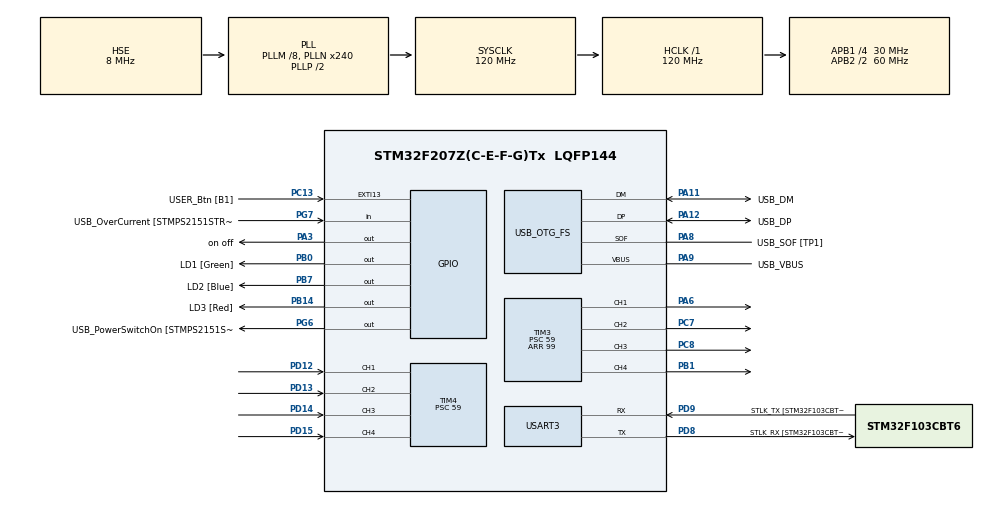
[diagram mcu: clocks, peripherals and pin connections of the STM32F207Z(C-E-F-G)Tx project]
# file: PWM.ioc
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Mcu.Family=STM32F2
Mcu.Name=STM32F207Z(C-E-F-G)Tx
Mcu.Package=LQFP144
NVIC.PriorityGroup=NVIC_PRIORITYGROUP_4
NVIC.TIM3_IRQn=true\:0\:0\:false\:false\:true\:true\:true\:true
NVIC.TIM4_IRQn=true\:0\:0\:false\:false\:true\:true\:true\:true
PA1.GPIO_Label=RMII_REF_CLK [LAN8742A-CZ-TR_REFCLK0]
PA1.Signal=ETH_REF_CLK
PA10.GPIO_Label=USB_ID
PA10.Signal=USB_OTG_FS_ID
PA11.GPIO_Label=USB_DM
PA11.Mode=Device_Only
PA11.Signal=USB_OTG_FS_DM
PA12.GPIO_Label=USB_DP
PA12.Mode=Device_Only
PA12.Signal=USB_OTG_FS_DP
PA13.GPIO_Label=TMS
PA13.Mode=Serial_Wire
PA13.Signal=SYS_JTMS-SWDIO
PA14.GPIO_Label=TCK
PA14.Mode=Serial_Wire
PA14.Signal=SYS_JTCK-SWCLK
PA2.GPIO_Label=RMII_MDIO [LAN8742A-CZ-TR_MDIO]
PA2.Signal=ETH_MDIO
PA3.GPIO_Label=on off
PA3.Signal=GPIO_Output
PA6.Signal=S_TIM3_CH1
PA7.GPIO_Label=RMII_CRS_DV [LAN8742A-CZ-TR_CRS_DV]
PA7.Signal=ETH_CRS_DV
PA8.GPIO_Label=USB_SOF [TP1]
PA8.Mode=Activate_SOF_FS
PA8.Signal=USB_OTG_FS_SOF
PA9.GPIO_Label=USB_VBUS
PA9.Mode=Activate_VBUS
PA9.Signal=USB_OTG_FS_VBUS
PB0.GPIO_Label=LD1 [Green]
PB0.Signal=GPIO_Output
PB1.Signal=S_TIM3_CH4
PB13.GPIO_Label=RMII_TXD1 [LAN8742A-CZ-TR_TXD1]
PB13.Signal=ETH_TXD1
PB14.GPIO_Label=LD3 [Red]
PB14.Signal=GPIO_Output
PB3.GPIO_Label=SWO
PB3.Signal=SYS_JTDO-SWO
PB7.GPIO_Label=LD2 [Blue]
PB7.Signal=GPIO_Output
PC1.GPIO_Label=RMII_MDC [LAN8742A-CZ-TR_MDC]
PC1.Signal=ETH_MDC
PC13.GPIO_Label=USER_Btn [B1]
PC13.Signal=GPXTI13
PC14-OSC32_IN.Mode=LSE-External-Oscillator
PC14-OSC32_IN.Signal=RCC_OSC32_IN
PC15-OSC32_OUT.Mode=LSE-External-Oscillator
PC15-OSC32_OUT.Signal=RCC_OSC32_OUT
PC4.GPIO_Label=RMII_RXD0 [LAN8742A-CZ-TR_RXD0]
PC4.Signal=ETH_RXD0
PC5.GPIO_Label=RMII_RXD1 [LAN8742A-CZ-TR_RXD1]
PC5.Signal=ETH_RXD1
PC7.Signal=S_TIM3_CH2
PC8.Signal=S_TIM3_CH3
PD12.Signal=S_TIM4_CH1
PD13.Signal=S_TIM4_CH2
PD14.Signal=S_TIM4_CH3
PD15.Signal=S_TIM4_CH4
PD8.GPIO_Label=STLK_RX [STM32F103CBT6_PA2]
PD8.Mode=Asynchronous
PD8.Signal=USART3_TX
PD9.GPIO_Label=STLK_TX [STM32F103CBT6_PA3]
PD9.Mode=Asynchronous
PD9.Signal=USART3_RX
PG11.GPIO_Label=RMII_TX_EN [LAN8742A-CZ-TR_TXEN]
PG11.Signal=ETH_TX_EN
PG13.GPIO_Label=RMII_TXD0 [LAN8742A-CZ-TR_TXD0]
PG13.Signal=ETH_TXD0
PG6.GPIO_Label=USB_PowerSwitchOn [STMPS2151STR_EN]
PG6.Signal=GPIO_Output
PG7.GPIO_Label=USB_OverCurrent [STMPS2151STR_FAULT]
PG7.Signal=GPIO_Input
PH0-OSC_IN.GPIO_Label=MCO [STM32F103CBT6_PA8]
PH0-OSC_IN.Mode=HSE-External-Oscillator
PH0-OSC_IN.Signal=RCC_OSC_IN
PH1-OSC_OUT.Mode=HSE-External-Oscillator
PH1-OSC_OUT.Signal=RCC_OSC_OUT
ProjectManager.HeapSize=0x200
ProjectManager.StackSize=0x400
ProjectManager.TargetToolchain=STM32CubeIDE
RCC.48MHZClocksFreq_Value=48000000
RCC.AHBFreq_Value=120000000
RCC.APB1CLKDivider=RCC_HCLK_DIV4
RCC.APB1Freq_Value=30000000
RCC.APB1TimFreq_Value=60000000
RCC.APB2CLKDivider=RCC_HCLK_DIV2
RCC.APB2Freq_Value=60000000
RCC.APB2TimFreq_Value=120000000
RCC.CortexFreq_Value=120000000
RCC.HCLKFreq_Value=120000000
RCC.HSE_VALUE=8000000
RCC.HSI_VALUE=16000000
RCC.PLLM=8
RCC.PLLMUL=RCC_PLL_MUL9
RCC.PLLN=240
RCC.PLLQ=5
RCC.PLLSourceVirtual=RCC_PLLSOURCE_HSE
RCC.PRESCALERUSB=RCC_USBCLKSOURCE_PLL_DIV1_5
RCC.SYSCLKFreq_VALUE=120000000
RCC.SYSCLKSource=RCC_SYSCLKSOURCE_PLLCLK
RCC.SYSCLKSourceVirtual=RCC_SYSCLKSOURCE_PLLCLK
RCC.USBFreq_Value=48000000
RCC.VCOOutputFreq_Value=240000000
SH.S_TIM3_CH1.0=TIM3_CH1,PWM Generation1 CH1
SH.S_TIM3_CH2.0=TIM3_CH2,PWM Generation2 CH2
SH.S_TIM3_CH3.0=TIM3_CH3,PWM Generation3 CH3
SH.S_TIM3_CH4.0=TIM3_CH4,PWM Generation4 CH4
SH.S_TIM4_CH1.0=TIM4_CH1,Input_Capture1_from_TI1
SH.S_TIM4_CH2.0=TIM4_CH2,Input_Capture2_from_TI2
SH.S_TIM4_CH3.0=TIM4_CH3,Input_Capture3_from_TI3
SH.S_TIM4_CH4.0=TIM4_CH4,Input_Capture4_from_TI4
TIM3.AutoReloadPreload=TIM_AUTORELOAD_PRELOAD_ENABLE
TIM3.Channel-PWM\ Generation1\ CH1=TIM_CHANNEL_1
TIM3.Channel-PWM\ Generation2\ CH2=TIM_CHANNEL_2
TIM3.Channel-PWM\ Generation3\ CH3=TIM_CHANNEL_3
TIM3.Channel-PWM\ Generation4\ CH4=TIM_CHANNEL_4
TIM3.Period=99
TIM3.Prescaler=59
TIM3.Pulse-PWM\ Generation1\ CH1=50
TIM3.Pulse-PWM\ Generation2\ CH2=50
TIM3.Pulse-PWM\ Generation3\ CH3=50
TIM3.Pulse-PWM\ Generation4\ CH4=50
TIM4.AutoReloadPreload=TIM_AUTORELOAD_PRELOAD_ENABLE
TIM4.Channel-Input_Capture1_from_TI1=TIM_CHANNEL_1
TIM4.Channel-Input_Capture2_from_TI2=TIM_CHANNEL_2
TIM4.Channel-Input_Capture3_from_TI3=TIM_CHANNEL_3
TIM4.Channel-Input_Capture4_from_TI4=TIM_CHANNEL_4
TIM4.Prescaler=59
USART3.VirtualMode=VM_ASYNC
USB_OTG_FS.VirtualMode=Device_Only
VP_TIM3_VS_ClockSourceINT.Mode=Internal
VP_TIM4_VS_ClockSourceINT.Mode=Internal
board=NUCLEO-F207ZG

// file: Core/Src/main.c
/* USER CODE BEGIN Header */
/**
  ******************************************************************************
  * @file           : main.c
  * @brief          : Main program body
  ******************************************************************************
  * @attention
  *
  * Copyright (c) 2024 STMicroelectronics.
  * All rights reserved.
  *
  * This software is licensed under terms that can be found in the LICENSE file
  * in the root directory of this software component.
  * If no LICENSE file comes with this software, it is provided AS-IS.
  *
  ******************************************************************************
  */
/* USER CODE END Header */
#include "main.h"

/* USER CODE BEGIN PD */
#define TIMCLOCK   60000000
#define PRESCALAR  60
/* USER CODE END PD */

TIM_HandleTypeDef htim3;
TIM_HandleTypeDef htim4;

UART_HandleTypeDef huart3;

PCD_HandleTypeDef hpcd_USB_OTG_FS;

void SystemClock_Config(void);
static void MX_GPIO_Init(void);
static void MX_USART3_UART_Init(void);
static void MX_USB_OTG_FS_PCD_Init(void);
static void MX_TIM3_Init(void);
static void MX_TIM4_Init(void);
/* USER CODE BEGIN PFP */
int frequency[4] = {0};
/* USER CODE END PFP */

/* USER CODE BEGIN 0 */
uint32_t IC_Val1 = 0;
uint32_t IC_Val2 = 0;
uint32_t Difference = 0;
int Is_First_Captured = 0;

/* Measure Frequency */

/* USER CODE END 0 */
void HAL_TIM_IC_CaptureCallback(TIM_HandleTypeDef *htim) {
    if (htim->Instance == TIM4) {
    	if (htim->Channel == HAL_TIM_ACTIVE_CHANNEL_1)
    		        {
    		            if (Is_First_Captured == 0)
    		            {
    		                IC_Val1 = HAL_TIM_ReadCapturedValue(htim, TIM_CHANNEL_1);
    		                Is_First_Captured = 1;
    		            }
    		            else
    		            {
    		                IC_Val2 = HAL_TIM_ReadCapturedValue(htim, TIM_CHANNEL_1);

    		                // Debug output

    		                if (IC_Val2 > IC_Val1)
    		                {
    		                    Difference = IC_Val2 - IC_Val1;
    		                }
    		                else
    		                {
    		                    Difference = (0xffff - IC_Val1) + IC_Val2;
    		                }

    		                if (Difference > 0)
    		                {
    		                    float refClock = TIMCLOCK / PRESCALAR;
    		                    frequency[0] = refClock / Difference;

    		                }

    		                __HAL_TIM_SET_COUNTER(htim, 0);
    		                Is_First_Captured = 0;
    		                HAL_TIM_IC_Stop_IT(&htim4, TIM_CHANNEL_1);
    		                HAL_TIM_IC_Start_IT(&htim4, TIM_CHANNEL_2);
    		            }
    		        }
    		    }if (htim->Channel == HAL_TIM_ACTIVE_CHANNEL_2)
		        {
		            if (Is_First_Captured == 0)
		            {
		                IC_Val1 = HAL_TIM_ReadCapturedValue(htim, TIM_CHANNEL_2);
		                Is_First_Captured = 1;
		            }
		            else
		            {
		                IC_Val2 = HAL_TIM_ReadCapturedValue(htim, TIM_CHANNEL_2);

		                // Debug output

		                if (IC_Val2 > IC_Val1)
		                {
		                    Difference = IC_Val2 - IC_Val1;
		                }
		                else
		                {
		                    Difference = (0xffff - IC_Val1) + IC_Val2;
		                }

		                if (Difference > 0)
		                {
		                    float refClock = TIMCLOCK / PRESCALAR;
		                    frequency[1] = refClock / Difference;

		                }

		                __HAL_TIM_SET_COUNTER(htim, 0);
		                Is_First_Captured = 0;
		                HAL_TIM_IC_Stop_IT(&htim4, TIM_CHANNEL_2);
		                HAL_TIM_IC_Start_IT(&htim4, TIM_CHANNEL_3);
		            }
		        }if (htim->Channel == HAL_TIM_ACTIVE_CHANNEL_3)
		        {
		            if (Is_First_Captured == 0)
		            {
		                IC_Val1 = HAL_TIM_ReadCapturedValue(htim, TIM_CHANNEL_3);
		                Is_First_Captured = 1;
		            }
		            else
		            {
		                IC_Val2 = HAL_TIM_ReadCapturedValue(htim, TIM_CHANNEL_3);

		                // Debug output

		                if (IC_Val2 > IC_Val1)
		                {
		                    Difference = IC_Val2 - IC_Val1;
		                }
		                else
		                {
		                    Difference = (0xffff - IC_Val1) + IC_Val2;
		                }

		                if (Difference > 0)
		                {
		                    float refClock = TIMCLOCK / PRESCALAR;
		                    frequency[2] = refClock / Difference;

		                }

		                __HAL_TIM_SET_COUNTER(htim, 0);
		                Is_First_Captured = 0;
		                HAL_TIM_IC_Stop_IT(&htim4, TIM_CHANNEL_3);
		                HAL_TIM_IC_Start_IT(&htim4, TIM_CHANNEL_4);
		            }
		        }if (htim->Channel == HAL_TIM_ACTIVE_CHANNEL_4)
		        {
		            if (Is_First_Captured == 0)
		            {
		                IC_Val1 = HAL_TIM_ReadCapturedValue(htim, TIM_CHANNEL_4);
		                Is_First_Captured = 1;
		            }
		            else
		            {
		                IC_Val2 = HAL_TIM_ReadCapturedValue(htim, TIM_CHANNEL_4);

		                // Debug output

		                if (IC_Val2 > IC_Val1)
		                {
		                    Difference = IC_Val2 - IC_Val1;
		                }
		                else
		                {
		                    Difference = (0xffff - IC_Val1) + IC_Val2;
		                }

		                if (Difference > 0)
		                {
		                    float refClock = TIMCLOCK / PRESCALAR;
		                    frequency[3] = refClock / Difference;

		                }

		                __HAL_TIM_SET_COUNTER(htim, 0);
		                Is_First_Captured = 0;
		                HAL_TIM_IC_Stop_IT(&htim4, TIM_CHANNEL_4);
		                HAL_TIM_IC_Start_IT(&htim4, TIM_CHANNEL_1);
		            }
		        }

    }

int main(void)
{

  /* MCU Configuration--------------------------------------------------------*/

  /* Reset of all peripherals, Initializes the Flash interface and the Systick. */
  HAL_Init();

  /* USER CODE BEGIN Init */
 // Array for storing frequency of each channel
  /* USER CODE END Init */

  /* Configure the system clock */
  SystemClock_Config();

  /* Initialize all configured peripherals */
  MX_GPIO_Init();
  MX_USART3_UART_Init();
  MX_USB_OTG_FS_PCD_Init();
  MX_TIM3_Init();
  MX_TIM4_Init();
  /* USER CODE BEGIN 2 */

  TIM3->CCR1 = 50;  // Set duty cycle for channel 1
  TIM3->CCR2 = 50; // Set duty cycle for channel 2
  TIM3->CCR3 = 50; // Set duty cycle for channel 3
  TIM3->CCR4 = 50; // Set duty cycle for channel 4
  HAL_TIM_PWM_Start(&htim3, TIM_CHANNEL_1);
  HAL_TIM_PWM_Start(&htim3, TIM_CHANNEL_2);
  HAL_TIM_PWM_Start(&htim3, TIM_CHANNEL_3);
  HAL_TIM_PWM_Start(&htim3, TIM_CHANNEL_4);

  HAL_TIM_IC_Start_IT(&htim4, TIM_CHANNEL_1);

  /* Infinite loop */
  while (1)
  {

  }
}

void SystemClock_Config(void)
{
  RCC_OscInitTypeDef RCC_OscInitStruct = {0};
  RCC_ClkInitTypeDef RCC_ClkInitStruct = {0};

  /** Initializes the RCC Oscillators according to the specified parameters
  * in the RCC_OscInitTypeDef structure.
  */
  RCC_OscInitStruct.OscillatorType = RCC_OSCILLATORTYPE_HSE;
  RCC_OscInitStruct.HSEState = RCC_HSE_ON;
  RCC_OscInitStruct.PLL.PLLState = RCC_PLL_ON;
  RCC_OscInitStruct.PLL.PLLSource = RCC_PLLSOURCE_HSE;
  RCC_OscInitStruct.PLL.PLLM = 8;
  RCC_OscInitStruct.PLL.PLLN = 240;
  RCC_OscInitStruct.PLL.PLLP = RCC_PLLP_DIV2;
  RCC_OscInitStruct.PLL.PLLQ = 5;
  if (HAL_RCC_OscConfig(&RCC_OscInitStruct) != HAL_OK)
  {
    Error_Handler();
  }

  /** Initializes the CPU, AHB and APB buses clocks
  */
  RCC_ClkInitStruct.ClockType = RCC_CLOCKTYPE_HCLK|RCC_CLOCKTYPE_SYSCLK
                              |RCC_CLOCKTYPE_PCLK1|RCC_CLOCKTYPE_PCLK2;
  RCC_ClkInitStruct.SYSCLKSource = RCC_SYSCLKSOURCE_PLLCLK;
  RCC_ClkInitStruct.AHBCLKDivider = RCC_SYSCLK_DIV1;
  RCC_ClkInitStruct.APB1CLKDivider = RCC_HCLK_DIV4;
  RCC_ClkInitStruct.APB2CLKDivider = RCC_HCLK_DIV2;

  if (HAL_RCC_ClockConfig(&RCC_ClkInitStruct, FLASH_LATENCY_3) != HAL_OK)
  {
    Error_Handler();
  }
}

static void MX_TIM3_Init(void)
{

  TIM_ClockConfigTypeDef sClockSourceConfig = {0};
  TIM_MasterConfigTypeDef sMasterConfig = {0};
  TIM_OC_InitTypeDef sConfigOC = {0};

  htim3.Instance = TIM3;
  htim3.Init.Prescaler = 59;
  htim3.Init.CounterMode = TIM_COUNTERMODE_UP;
  htim3.Init.Period = 99;
  htim3.Init.ClockDivision = TIM_CLOCKDIVISION_DIV1;
  htim3.Init.AutoReloadPreload = TIM_AUTORELOAD_PRELOAD_ENABLE;
  if (HAL_TIM_Base_Init(&htim3) != HAL_OK)
  {
    Error_Handler();
  }
  sClockSourceConfig.ClockSource = TIM_CLOCKSOURCE_INTERNAL;
  if (HAL_TIM_ConfigClockSource(&htim3, &sClockSourceConfig) != HAL_OK)
  {
    Error_Handler();
  }
  if (HAL_TIM_PWM_Init(&htim3) != HAL_OK)
  {
    Error_Handler();
  }
  sMasterConfig.MasterOutputTrigger = TIM_TRGO_RESET;
  sMasterConfig.MasterSlaveMode = TIM_MASTERSLAVEMODE_DISABLE;
  if (HAL_TIMEx_MasterConfigSynchronization(&htim3, &sMasterConfig) != HAL_OK)
  {
    Error_Handler();
  }
  sConfigOC.OCMode = TIM_OCMODE_PWM1;
  sConfigOC.Pulse = 50;
  sConfigOC.OCPolarity = TIM_OCPOLARITY_HIGH;
  sConfigOC.OCFastMode = TIM_OCFAST_DISABLE;
  if (HAL_TIM_PWM_ConfigChannel(&htim3, &sConfigOC, TIM_CHANNEL_1) != HAL_OK)
  {
    Error_Handler();
  }
  if (HAL_TIM_PWM_ConfigChannel(&htim3, &sConfigOC, TIM_CHANNEL_2) != HAL_OK)
  {
    Error_Handler();
  }
  if (HAL_TIM_PWM_ConfigChannel(&htim3, &sConfigOC, TIM_CHANNEL_3) != HAL_OK)
  {
    Error_Handler();
  }
  if (HAL_TIM_PWM_ConfigChannel(&htim3, &sConfigOC, TIM_CHANNEL_4) != HAL_OK)
  {
    Error_Handler();
  }
  HAL_TIM_MspPostInit(&htim3);

}

static void MX_TIM4_Init(void)
{

  TIM_ClockConfigTypeDef sClockSourceConfig = {0};
  TIM_MasterConfigTypeDef sMasterConfig = {0};
  TIM_IC_InitTypeDef sConfigIC = {0};

  htim4.Instance = TIM4;
  htim4.Init.Prescaler = 59;
  htim4.Init.CounterMode = TIM_COUNTERMODE_UP;
  htim4.Init.Period = 65535;
  htim4.Init.ClockDivision = TIM_CLOCKDIVISION_DIV1;
  htim4.Init.AutoReloadPreload = TIM_AUTORELOAD_PRELOAD_ENABLE;
  if (HAL_TIM_Base_Init(&htim4) != HAL_OK)
  {
    Error_Handler();
  }
  sClockSourceConfig.ClockSource = TIM_CLOCKSOURCE_INTERNAL;
  if (HAL_TIM_ConfigClockSource(&htim4, &sClockSourceConfig) != HAL_OK)
  {
    Error_Handler();
  }
  if (HAL_TIM_IC_Init(&htim4) != HAL_OK)
  {
    Error_Handler();
  }
  sMasterConfig.MasterOutputTrigger = TIM_TRGO_RESET;
  sMasterConfig.MasterSlaveMode = TIM_MASTERSLAVEMODE_DISABLE;
  if (HAL_TIMEx_MasterConfigSynchronization(&htim4, &sMasterConfig) != HAL_OK)
  {
    Error_Handler();
  }
  sConfigIC.ICPolarity = TIM_INPUTCHANNELPOLARITY_RISING;
  sConfigIC.ICSelection = TIM_ICSELECTION_DIRECTTI;
  sConfigIC.ICPrescaler = TIM_ICPSC_DIV1;
  sConfigIC.ICFilter = 0;
  if (HAL_TIM_IC_ConfigChannel(&htim4, &sConfigIC, TIM_CHANNEL_1) != HAL_OK)
  {
    Error_Handler();
  }
  if (HAL_TIM_IC_ConfigChannel(&htim4, &sConfigIC, TIM_CHANNEL_2) != HAL_OK)
  {
    Error_Handler();
  }
  if (HAL_TIM_IC_ConfigChannel(&htim4, &sConfigIC, TIM_CHANNEL_3) != HAL_OK)
  {
    Error_Handler();
  }
  if (HAL_TIM_IC_ConfigChannel(&htim4, &sConfigIC, TIM_CHANNEL_4) != HAL_OK)
  {
    Error_Handler();
  }

}

static void MX_USART3_UART_Init(void)
{

  huart3.Instance = USART3;
  huart3.Init.BaudRate = 115200;
  huart3.Init.WordLength = UART_WORDLENGTH_8B;
  huart3.Init.StopBits = UART_STOPBITS_1;
  huart3.Init.Parity = UART_PARITY_NONE;
  huart3.Init.Mode = UART_MODE_TX_RX;
  huart3.Init.HwFlowCtl = UART_HWCONTROL_NONE;
  huart3.Init.OverSampling = UART_OVERSAMPLING_16;
  if (HAL_UART_Init(&huart3) != HAL_OK)
  {
    Error_Handler();
  }

}

static void MX_USB_OTG_FS_PCD_Init(void)
{

  hpcd_USB_OTG_FS.Instance = USB_OTG_FS;
  hpcd_USB_OTG_FS.Init.dev_endpoints = 4;
  hpcd_USB_OTG_FS.Init.speed = PCD_SPEED_FULL;
  hpcd_USB_OTG_FS.Init.dma_enable = DISABLE;
  hpcd_USB_OTG_FS.Init.phy_itface = PCD_PHY_EMBEDDED;
  hpcd_USB_OTG_FS.Init.Sof_enable = ENABLE;
  hpcd_USB_OTG_FS.Init.low_power_enable = DISABLE;
  hpcd_USB_OTG_FS.Init.vbus_sensing_enable = ENABLE;
  hpcd_USB_OTG_FS.Init.use_dedicated_ep1 = DISABLE;
  if (HAL_PCD_Init(&hpcd_USB_OTG_FS) != HAL_OK)
  {
    Error_Handler();
  }

}

static void MX_GPIO_Init(void)
{
  GPIO_InitTypeDef GPIO_InitStruct = {0};

  /* GPIO Ports Clock Enable */
  __HAL_RCC_GPIOC_CLK_ENABLE();
  __HAL_RCC_GPIOH_CLK_ENABLE();
  __HAL_RCC_GPIOA_CLK_ENABLE();
  __HAL_RCC_GPIOB_CLK_ENABLE();
  __HAL_RCC_GPIOD_CLK_ENABLE();
  __HAL_RCC_GPIOG_CLK_ENABLE();

  /*Configure GPIO pin Output Level */
  HAL_GPIO_WritePin(on_off_GPIO_Port, on_off_Pin, GPIO_PIN_RESET);

  /*Configure GPIO pin Output Level */
  HAL_GPIO_WritePin(GPIOB, LD1_Pin|LD3_Pin|LD2_Pin, GPIO_PIN_RESET);

  /*Configure GPIO pin Output Level */
  HAL_GPIO_WritePin(USB_PowerSwitchOn_GPIO_Port, USB_PowerSwitchOn_Pin, GPIO_PIN_RESET);

  /*Configure GPIO pin : USER_Btn_Pin */
  GPIO_InitStruct.Pin = USER_Btn_Pin;
  GPIO_InitStruct.Mode = GPIO_MODE_IT_RISING;
  GPIO_InitStruct.Pull = GPIO_NOPULL;
  HAL_GPIO_Init(USER_Btn_GPIO_Port, &GPIO_InitStruct);

  /*Configure GPIO pins : RMII_MDC_Pin RMII_RXD0_Pin RMII_RXD1_Pin */
  GPIO_InitStruct.Pin = RMII_MDC_Pin|RMII_RXD0_Pin|RMII_RXD1_Pin;
  GPIO_InitStruct.Mode = GPIO_MODE_AF_PP;
  GPIO_InitStruct.Pull = GPIO_NOPULL;
  GPIO_InitStruct.Speed = GPIO_SPEED_FREQ_VERY_HIGH;
  GPIO_InitStruct.Alternate = GPIO_AF11_ETH;
  HAL_GPIO_Init(GPIOC, &GPIO_InitStruct);

  /*Configure GPIO pins : RMII_REF_CLK_Pin RMII_MDIO_Pin RMII_CRS_DV_Pin */
  GPIO_InitStruct.Pin = RMII_REF_CLK_Pin|RMII_MDIO_Pin|RMII_CRS_DV_Pin;
  GPIO_InitStruct.Mode = GPIO_MODE_AF_PP;
  GPIO_InitStruct.Pull = GPIO_NOPULL;
  GPIO_InitStruct.Speed = GPIO_SPEED_FREQ_VERY_HIGH;
  GPIO_InitStruct.Alternate = GPIO_AF11_ETH;
  HAL_GPIO_Init(GPIOA, &GPIO_InitStruct);

  /*Configure GPIO pin : on_off_Pin */
  GPIO_InitStruct.Pin = on_off_Pin;
  GPIO_InitStruct.Mode = GPIO_MODE_OUTPUT_PP;
  GPIO_InitStruct.Pull = GPIO_NOPULL;
  GPIO_InitStruct.Speed = GPIO_SPEED_FREQ_LOW;
  HAL_GPIO_Init(on_off_GPIO_Port, &GPIO_InitStruct);

  /*Configure GPIO pins : LD1_Pin LD3_Pin LD2_Pin */
  GPIO_InitStruct.Pin = LD1_Pin|LD3_Pin|LD2_Pin;
  GPIO_InitStruct.Mode = GPIO_MODE_OUTPUT_PP;
  GPIO_InitStruct.Pull = GPIO_NOPULL;
  GPIO_InitStruct.Speed = GPIO_SPEED_FREQ_LOW;
  HAL_GPIO_Init(GPIOB, &GPIO_InitStruct);

  /*Configure GPIO pin : RMII_TXD1_Pin */
  GPIO_InitStruct.Pin = RMII_TXD1_Pin;
  GPIO_InitStruct.Mode = GPIO_MODE_AF_PP;
  GPIO_InitStruct.Pull = GPIO_NOPULL;
  GPIO_InitStruct.Speed = GPIO_SPEED_FREQ_VERY_HIGH;
  GPIO_InitStruct.Alternate = GPIO_AF11_ETH;
  HAL_GPIO_Init(RMII_TXD1_GPIO_Port, &GPIO_InitStruct);

  /*Configure GPIO pin : USB_PowerSwitchOn_Pin */
  GPIO_InitStruct.Pin = USB_PowerSwitchOn_Pin;
  GPIO_InitStruct.Mode = GPIO_MODE_OUTPUT_PP;
  GPIO_InitStruct.Pull = GPIO_NOPULL;
  GPIO_InitStruct.Speed = GPIO_SPEED_FREQ_LOW;
  HAL_GPIO_Init(USB_PowerSwitchOn_GPIO_Port, &GPIO_InitStruct);

  /*Configure GPIO pin : USB_OverCurrent_Pin */
  GPIO_InitStruct.Pin = USB_OverCurrent_Pin;
  GPIO_InitStruct.Mode = GPIO_MODE_INPUT;
  GPIO_InitStruct.Pull = GPIO_NOPULL;
  HAL_GPIO_Init(USB_OverCurrent_GPIO_Port, &GPIO_InitStruct);

  /*Configure GPIO pins : RMII_TX_EN_Pin RMII_TXD0_Pin */
  GPIO_InitStruct.Pin = RMII_TX_EN_Pin|RMII_TXD0_Pin;
  GPIO_InitStruct.Mode = GPIO_MODE_AF_PP;
  GPIO_InitStruct.Pull = GPIO_NOPULL;
  GPIO_InitStruct.Speed = GPIO_SPEED_FREQ_VERY_HIGH;
  GPIO_InitStruct.Alternate = GPIO_AF11_ETH;
  HAL_GPIO_Init(GPIOG, &GPIO_InitStruct);

}

void Error_Handler(void)
{
  __disable_irq();
  while (1)
  {
  }
}
